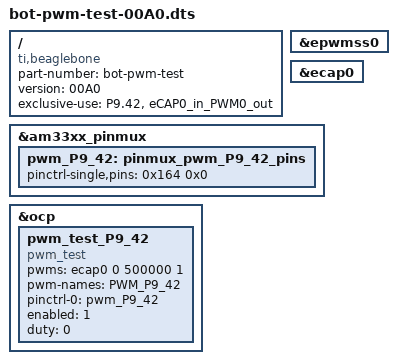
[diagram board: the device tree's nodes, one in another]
/dts-v1/;
/plugin/;
/{
  compatible = "ti,beaglebone", "ti,beaglebone-black";
  /* identification */
  part-number = "bot-pwm-test";
  version = "00A0";

  exclusive-use =
    "P9.42",
    "eCAP0_in_PWM0_out";

  fragment@0 {
    target = <&epwmss0>;
    __overlay__ {
      status = "okay";
    };
  };

  fragment@1 {
    target = <&ecap0>;
    __overlay__ {
      status = "okay";
    };
  };

  fragment@2 {
    target = <&am33xx_pinmux>;
    __overlay__ {
      pwm_P9_42: pinmux_pwm_P9_42_pins {
        pinctrl-single,pins = <0x164 0x0>;
      };
    };
  };

  fragment@3 {
    target = <&ocp>;
    __overlay__ {
      pwm_test_P9_42 {
        compatible = "pwm_test";
        pwms = <&ecap0 0 500000 1>;
        pwm-names = "PWM_P9_42";
        pinctrl-names = "default";
        pinctrl-0 = <&pwm_P9_42>;
        enabled = <1>;
        duty = <0>;
        status = "okay";
      };
    };
  };
};

